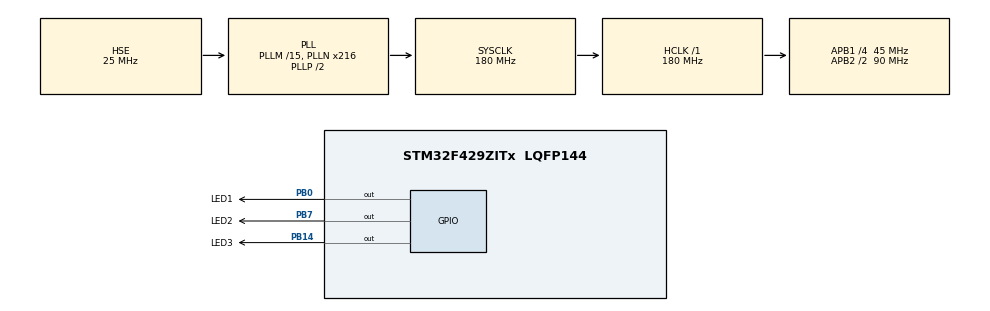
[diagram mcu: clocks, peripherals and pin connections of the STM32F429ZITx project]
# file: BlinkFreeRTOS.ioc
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FREERTOS.Tasks01=defaultTask,24,128,StartDefaultTask,Default,NULL,Dynamic,NULL,NULL
Mcu.Family=STM32F4
Mcu.Name=STM32F429ZITx
Mcu.Package=LQFP144
NVIC.PriorityGroup=NVIC_PRIORITYGROUP_4
NVIC.TIM7_IRQn=true\:15\:0\:false\:false\:true\:false\:false\:true\:true
NVIC.TimeBase=TIM7_IRQn
NVIC.TimeBaseIP=TIM7
PA13.Mode=Serial_Wire
PA13.Signal=SYS_JTMS-SWDIO
PA14.Mode=Serial_Wire
PA14.Signal=SYS_JTCK-SWCLK
PB0.GPIO_Label=LED1
PB0.Signal=GPIO_Output
PB14.GPIO_Label=LED3
PB14.Signal=GPIO_Output
PB7.GPIO_Label=LED2
PB7.Signal=GPIO_Output
PH0/OSC_IN.Mode=HSE-External-Oscillator
PH0/OSC_IN.Signal=RCC_OSC_IN
PH1/OSC_OUT.Mode=HSE-External-Oscillator
PH1/OSC_OUT.Signal=RCC_OSC_OUT
ProjectManager.HeapSize=0x200
ProjectManager.StackSize=0x400
ProjectManager.TargetToolchain=STM32CubeIDE
RCC.48MHZClocksFreq_Value=90000000
RCC.AHBFreq_Value=180000000
RCC.APB1CLKDivider=RCC_HCLK_DIV4
RCC.APB1Freq_Value=45000000
RCC.APB1TimFreq_Value=90000000
RCC.APB2CLKDivider=RCC_HCLK_DIV2
RCC.APB2Freq_Value=90000000
RCC.APB2TimFreq_Value=180000000
RCC.CortexFreq_Value=180000000
RCC.HCLKFreq_Value=180000000
RCC.HSE_VALUE=25000000
RCC.HSI_VALUE=16000000
RCC.LSE_VALUE=32768
RCC.PLLM=15
RCC.PLLN=216
RCC.PLLSourceVirtual=RCC_PLLSOURCE_HSE
RCC.SYSCLKFreq_VALUE=180000000
RCC.SYSCLKSource=RCC_SYSCLKSOURCE_PLLCLK
RCC.VCOOutputFreq_Value=360000000
VP_FREERTOS_VS_CMSIS_V2.Mode=CMSIS_V2
VP_SYS_VS_tim7.Mode=TIM7
board=custom

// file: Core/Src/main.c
/* USER CODE BEGIN Header */
/**
  ******************************************************************************
  * @file           : main.c
  * @brief          : Main program body
  ******************************************************************************
  * @attention
  *
  * Copyright (c) 2024 STMicroelectronics.
  * All rights reserved.
  *
  * This software is licensed under terms that can be found in the LICENSE file
  * in the root directory of this software component.
  * If no LICENSE file comes with this software, it is provided AS-IS.
  *
  ******************************************************************************
  */
/* USER CODE END Header */
#include "main.h"
#include "cmsis_os.h"

/* Definitions for defaultTask */
osThreadId_t led1TaskHandle;
const osThreadAttr_t led1Task_attributes = {
  .name = "LED1Task",
  .stack_size = 128 * 4,
  .priority = (osPriority_t) osPriorityNormal,
};
osThreadId_t led2TaskHandle;
const osThreadAttr_t led2Task_attributes = {
  .name = "LED2Task",
  .stack_size = 128 * 4,
  .priority = (osPriority_t) osPriorityNormal,
};
osThreadId_t led3TaskHandle;
const osThreadAttr_t led3Task_attributes = {
  .name = "LED3Task",
  .stack_size = 128 * 4,
  .priority = (osPriority_t) osPriorityNormal,
};

void SystemClock_Config(void);
static void MX_GPIO_Init(void);
void LED1Task(void *argument);
void LED2Task(void *argument);
void LED3Task(void *argument);

int main(void)
{

  /* MCU Configuration--------------------------------------------------------*/

  /* Reset of all peripherals, Initializes the Flash interface and the Systick. */
  HAL_Init();

  /* Configure the system clock */
  SystemClock_Config();

  /* Initialize all configured peripherals */
  MX_GPIO_Init();

  /* Init scheduler */
  osKernelInitialize();

  /* Create the thread(s) */
  /* creation of defaultTask */
  led1TaskHandle = osThreadNew(LED1Task, NULL, &led1Task_attributes);
  led2TaskHandle = osThreadNew(LED2Task, NULL, &led2Task_attributes);
  led3TaskHandle = osThreadNew(LED3Task, NULL, &led3Task_attributes);

  /* Start scheduler */
  osKernelStart();

  /* We should never get here as control is now taken by the scheduler */
  /* Infinite loop */
  while (1)
  {

  }
}

void SystemClock_Config(void)
{
  RCC_OscInitTypeDef RCC_OscInitStruct = {0};
  RCC_ClkInitTypeDef RCC_ClkInitStruct = {0};

  /** Configure the main internal regulator output voltage
  */
  __HAL_RCC_PWR_CLK_ENABLE();
  __HAL_PWR_VOLTAGESCALING_CONFIG(PWR_REGULATOR_VOLTAGE_SCALE1);

  /** Initializes the RCC Oscillators according to the specified parameters
  * in the RCC_OscInitTypeDef structure.
  */
  RCC_OscInitStruct.OscillatorType = RCC_OSCILLATORTYPE_HSE;
  RCC_OscInitStruct.HSEState = RCC_HSE_ON;
  RCC_OscInitStruct.PLL.PLLState = RCC_PLL_ON;
  RCC_OscInitStruct.PLL.PLLSource = RCC_PLLSOURCE_HSE;
  RCC_OscInitStruct.PLL.PLLM = 15;
  RCC_OscInitStruct.PLL.PLLN = 216;
  RCC_OscInitStruct.PLL.PLLP = RCC_PLLP_DIV2;
  RCC_OscInitStruct.PLL.PLLQ = 4;
  if (HAL_RCC_OscConfig(&RCC_OscInitStruct) != HAL_OK)
  {
    Error_Handler();
  }

  /** Activate the Over-Drive mode
  */
  if (HAL_PWREx_EnableOverDrive() != HAL_OK)
  {
    Error_Handler();
  }

  /** Initializes the CPU, AHB and APB buses clocks
  */
  RCC_ClkInitStruct.ClockType = RCC_CLOCKTYPE_HCLK|RCC_CLOCKTYPE_SYSCLK
                              |RCC_CLOCKTYPE_PCLK1|RCC_CLOCKTYPE_PCLK2;
  RCC_ClkInitStruct.SYSCLKSource = RCC_SYSCLKSOURCE_PLLCLK;
  RCC_ClkInitStruct.AHBCLKDivider = RCC_SYSCLK_DIV1;
  RCC_ClkInitStruct.APB1CLKDivider = RCC_HCLK_DIV4;
  RCC_ClkInitStruct.APB2CLKDivider = RCC_HCLK_DIV2;

  if (HAL_RCC_ClockConfig(&RCC_ClkInitStruct, FLASH_LATENCY_5) != HAL_OK)
  {
    Error_Handler();
  }
}

static void MX_GPIO_Init(void)
{
  GPIO_InitTypeDef GPIO_InitStruct = {0};

  /* GPIO Ports Clock Enable */
  __HAL_RCC_GPIOH_CLK_ENABLE();
  __HAL_RCC_GPIOB_CLK_ENABLE();
  __HAL_RCC_GPIOA_CLK_ENABLE();

  /*Configure GPIO pin Output Level */
  HAL_GPIO_WritePin(GPIOB, LED1_Pin|LED3_Pin|LED2_Pin, GPIO_PIN_RESET);

  /*Configure GPIO pins : LED1_Pin LED3_Pin LED2_Pin */
  GPIO_InitStruct.Pin = LED1_Pin|LED3_Pin|LED2_Pin;
  GPIO_InitStruct.Mode = GPIO_MODE_OUTPUT_PP;
  GPIO_InitStruct.Pull = GPIO_NOPULL;
  GPIO_InitStruct.Speed = GPIO_SPEED_FREQ_LOW;
  HAL_GPIO_Init(GPIOB, &GPIO_InitStruct);

}

void LED1Task(void *argument)
{
  /* USER CODE BEGIN 5 */
  /* Infinite loop */
  for(;;)
  {
	  HAL_GPIO_WritePin(LED1_GPIO_Port,LED1_Pin,GPIO_PIN_RESET);
	  osDelay(250);
	  HAL_GPIO_WritePin(LED1_GPIO_Port,LED1_Pin,GPIO_PIN_SET);
	  osDelay(250);
  }
  /* USER CODE END 5 */
}

void LED2Task(void *argument)
{
  /* USER CODE BEGIN 5 */
  /* Infinite loop */
  for(;;)
  {
	  HAL_GPIO_WritePin(LED2_GPIO_Port,LED2_Pin,GPIO_PIN_RESET);
	  osDelay(500);
	  HAL_GPIO_WritePin(LED2_GPIO_Port,LED2_Pin,GPIO_PIN_SET);
	  osDelay(500);
  }
  /* USER CODE END 5 */
}

void LED3Task(void *argument)
{
  /* USER CODE BEGIN 5 */
  /* Infinite loop */
  for(;;)
  {
	  HAL_GPIO_WritePin(LED3_GPIO_Port,LED3_Pin,GPIO_PIN_RESET);
	  osDelay(1000);
	  HAL_GPIO_WritePin(LED3_GPIO_Port,LED3_Pin,GPIO_PIN_SET);
	  osDelay(1000);
  }
  /* USER CODE END 5 */
}

void HAL_TIM_PeriodElapsedCallback(TIM_HandleTypeDef *htim)
{
  if (htim->Instance == TIM7) {
    HAL_IncTick();
  }
}

void Error_Handler(void)
{
  __disable_irq();
  while (1)
  {
  }
}
